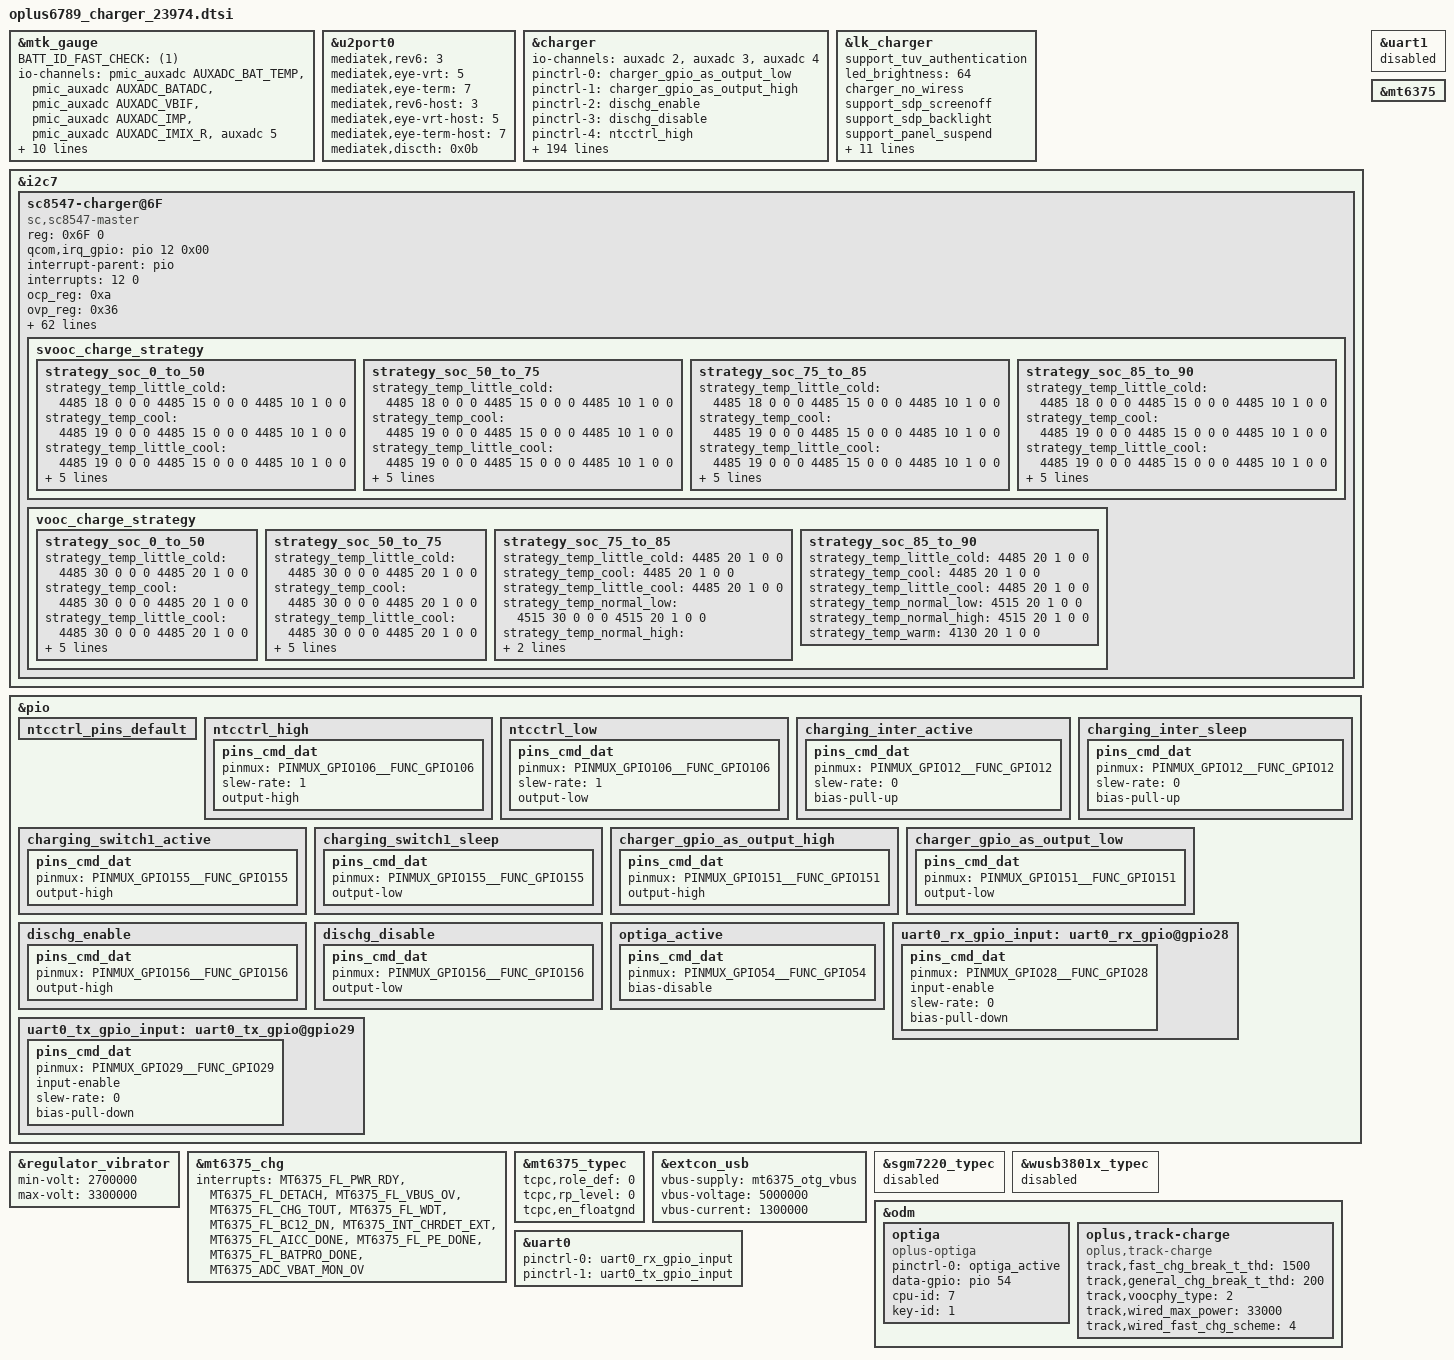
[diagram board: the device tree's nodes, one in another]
/*
 *
 * CPU:MT6789 changzheng
 * IRQB
 * CHG_INT(cp irq)                --> GPIO12(CP1)/GPIO10(CP2)
 * CC_INTB(cc login irq)          --> GPIO3
 * EINT_CHG_M(main irq)           --> GPIO4
 *
 * GPIO
 * MAIN/CCLOGIN_SCL               --> GPIO48(SCL5)
 * MAIN/CCLOGIN_SDA               --> GPIO49(SDA5)
 * SW_CTRL(uart/vooc switch)      --> GPIO155(USB_SWITCH_2)
 * DISCHARGE_EN(防烧口)           -->
 * CHARGER_PUMP1_SCL               --> GPIO144(CP1_SCL7)
 * CHARGER_PUMP1_SDA               --> GPIO145(CP1_SDA7)
 * USB_ON(usb/uart&vooc switch)    --> GPIO151(USB_SWITCH_1)
 *
 * AUXADC:
 * 0				-->
 * 1				-->
 * 2				--> USB_TEM1_ADC
 * 3				--> USB_TEM2_ADC
 * 4				--> BAT_ID_ADC_OUT
 * 5				--> SUB_BAT_TEM
 * 6				-->
 * 7				-->
 * 8				-->
 */

#include <dt-bindings/iio/mt635x-auxadc.h>
#include <dt-bindings/mfd/mt6375.h>

&mtk_gauge {
	status = "okay";
	BATT_ID_FAST_CHECK = <(1)>;
	io-channels = <&pmic_auxadc AUXADC_BAT_TEMP>,
		<&pmic_auxadc AUXADC_BATADC>,
		<&pmic_auxadc AUXADC_VBIF>,
		<&pmic_auxadc AUXADC_IMP>,
		<&pmic_auxadc AUXADC_IMIX_R>,
		<&auxadc 5>;
	io-channel-names = "pmic_battery_temp",
		"pmic_battery_voltage",
		"pmic_bif_voltage",
		"pmic_ptim_voltage",
		"pmic_ptim_r",
		"auxadc4-batt_id_v";
	charger = <&mt6375_chg>;
	FUELGAGUE_APPLY = <(1)>;
	ntc_switch_gpio = <&pio 106 0x00>;
	NTC_SWITCH_NOT_USE = <(1)>;
	//IS_SUBBOARD_TEMP_SUPPORT = <(1)>;
	Enable_Is_Force_Full = <(1)>;
	DIM2_TABLE_DISTINGUISH = <(1)>;
	EMBEDDED_SEL = <(1)>;
	CAR_TUNE_VALUE = <(99)>;
	FG_METER_RESISTANCE = <70>;
	COM_FG_METER_RESISTANCE = <70>;
	#include "mediatek/bat_setting/mt6789_23974_battery_prop_dim2_ext.dtsi"
	#include "mediatek/bat_setting/mt6789_23974_battery_table_ext.dtsi"
};

&u2port0 {
	mediatek,rev6 = <3>;
	mediatek,eye-vrt = <5>;
	mediatek,eye-term = <7>;
	mediatek,rev6-host = <3>;
	mediatek,eye-vrt-host = <5>;
	mediatek,eye-term-host = <7>;
	mediatek,discth = <0x0b>;
};

&charger {

	io-channels = <&auxadc 2>,<&auxadc 3>,<&auxadc 4>;
	io-channel-names = "usb_temp_v_l","usb_temp_v_r",
		"auxadc3-chargeric_temp";

	pinctrl-names = "charger_gpio_as_output_low","charger_gpio_as_output_high",
		"dischg_enable","dischg_disable","ntcctrl_high","ntcctrl_low";
	pinctrl-0 = <&charger_gpio_as_output_low>;
	pinctrl-1 = <&charger_gpio_as_output_high>;
	pinctrl-2 = <&dischg_enable>;
	pinctrl-3 = <&dischg_disable>;
	pinctrl-4 = <&ntcctrl_high>;
	pinctrl-5 = <&ntcctrl_low>;

	gauge = <&mtk_gauge>;
	charger = <&mt6375_chg>;

	//for oplus chg framework:
	qcom,pd_input_current_charger_ma = <2000>;
	qcom,qc_input_current_charger_ma = <2000>;
	qcom,input_current_charger_ma = <2200>;
	qcom,input_current_usb_ma = <500>;
	qcom,input_current_cdp_ma = <1500>;
	qcom,input_current_camera_ma = <1200>;
	qcom,input_current_calling_ma = <1500>;

	qcom,led_warm_bat_decidegc = <350>;
	qcom,led_high_bat_decidegc = <370>;
	qcom,input_current_led_ma = <1500>;
	qcom,input_current_led_ma_high = <1500>;
	qcom,input_current_led_ma_warm = <2000>;
	qcom,input_current_led_ma_normal = <2000>;
	qcom,input_current_led_ma_forcmcc = <500>;
	qcom,input_current_led_ma_limit_high = <1500>;

	qcom,vooc_temp_bat_normal_decidegc = <350>;
	qcom,vooc_temp_bat_warm_decidegc = <370>;
	qcom,vooc_temp_bat_hot_decidegc = <440>;
	qcom,input_current_vooc_led_ma_high = <1200>;
	qcom,input_current_vooc_led_ma_warm = <1800>;
	qcom,input_current_vooc_led_ma_normal = <3600>;
	qcom,input_current_vooc_ma_normal = <3600>;
	qcom,input_current_vooc_ma_warm = <3200>;
	qcom,input_current_vooc_ma_high = <2200>;

	qcom,overtemp_bat_decidegc = <400>;
	qcom,iterm_disabled = <0>;
	//sw_full_count = <25>;
	qcom,iterm_ma = <404>;
	qcom,recharge-mv = <100>;

	qcom,batt_capacity_mah = <7880>; /*typical capacity*/
	//qcom,batt_capacity_mah = <4880>; /*rated capacity*/
	qcom,usb_high_than_bat_decidegc = <168>;

	qcom,removed_bat_decidegc = <390>;  /* < -39C */

	qcom,cold_bat_decidegc = <100>;  /* -10C ~ 0C */
	qcom,temp_cold_vfloat_mv = <4435>;
	qcom,temp_freeze_fastchg_current_ma_high = <1500>;
	qcom,temp_freeze_fastchg_current_ma_low = <1500>;
	qcom,temp_freeze_fastchg_current_ma = <1500>;
	qcom,temp_cold_fastchg_current_ma_high = <1500>;
	qcom,temp_cold_fastchg_current_ma_low = <1500>;
	qcom,temp_cold_fastchg_current_ma = <1500>;

	qcom,little_cold_bat_decidegc = <0>;    /* 0C ~ 5C */
	qcom,temp_little_cold_vfloat_mv = <4435>;
	qcom,temp_little_cold_fastchg_current_ma_high = <2000>;
	qcom,temp_little_cold_fastchg_current_ma_low = <2000>;
	qcom,temp_little_cold_fastchg_current_ma = <2000>;
	qcom,qc_temp_little_cold_fastchg_current_ma_high = <3000>;
	qcom,qc_temp_little_cold_fastchg_current_ma_low = <2700>;
	qcom,pd_temp_little_cold_fastchg_current_ma_high = <3000>;
	qcom,pd_temp_little_cold_fastchg_current_ma_low = <2700>;

	qcom,cool_bat_decidegc = <50>;  /* 5C ~ 12C */
	qcom,temp_cool_vfloat_mv = <4435>;
	qcom,temp_cool_fastchg_current_ma_high = <2000>;
	qcom,temp_cool_fastchg_current_ma_low = <2000>;
	qcom,qc_temp_cool_fastchg_current_ma_high = <3000>;
	qcom,qc_temp_cool_fastchg_current_ma_low = <3000>;
	qcom,pd_temp_cool_fastchg_current_ma_high = <3000>;
	qcom,pd_temp_cool_fastchg_current_ma_low = <3000>;

	qcom,little_cool_bat_decidegc = <120>;  /* 12C ~ 16C */
	qcom,temp_little_cool_vfloat_mv = <4435>;
	qcom,temp_little_cool_fastchg_current_ma = <2000>;
	qcom,pd_temp_little_cool_fastchg_current_ma = <3000>;
	qcom,qc_temp_little_cool_fastchg_current_ma = <3000>;

	qcom,normal_bat_decidegc = <160>;       /* 16C ~ 45C */
	qcom,temp_normal_vfloat_mv = <4435>;
	qcom,temp_normal_fastchg_current_ma = <2000>;
	qcom,pd_temp_normal_fastchg_current_ma = <3000>;
	qcom,qc_temp_normal_fastchg_current_ma = <3000>;

	qcom,warm_bat_decidegc = <450>;         /* 45C ~ 53C */ /*8pin Bat Vooc project need add 3 degree C*/
	qcom,temp_warm_vfloat_mv = <4130>;
	qcom,temp_warm_fastchg_current_ma = <1152>;
	qcom,pd_temp_warm_fastchg_current_ma = <1152>;
	qcom,qc_temp_warm_fastchg_current_ma = <1152>;
	qcom,temp_warm_fastchg_current_ma_led_on = <500>;

	qcom,hot_bat_decidegc = <530>;  /* > 53C */

	qcom,non_standard_vfloat_mv = <3980>;
	qcom,non_standard_fastchg_current_ma = <512>;

	qcom,short_c_bat_cv_mv = <4330>;
	qcom,short_c_bat_vfloat_mv = <3800>;
	qcom,short_c_bat_fastchg_current_ma = <512>;
	qcom,short_c_bat_vfloat_sw_limit = <3750>;

	qcom,cold_vfloat_sw_limit = <4385>;
	qcom,little_cold_vfloat_sw_limit = <4385>;
	qcom,cool_vfloat_sw_limit = <4385>;
	qcom,little_cool_vfloat_sw_limit = <4385>;
	qcom,normal_vfloat_sw_limit = <4385>;
	qcom,warm_vfloat_sw_limit = <4080>;
	qcom,non_standard_vfloat_sw_limit = <3930>;

	qcom,max_chg_time_sec = <72000>;
	qcom,charger_hv_thr = <10000>;
	qcom,charger_recv_thr = <9800>;
	qcom,charger_lv_thr = <3400>;
	qcom,vbatt_full_thr = <4400>;
	qcom,vbatt_hv_thr = <4600>;

	qcom,vfloat_step_mv = <16>;
	qcom,non_standard_vfloat_over_sw_limit = <3990>;
	qcom,cold_vfloat_over_sw_limit = <4445>;
	qcom,little_cold_vfloat_over_sw_limit = <4445>;
	qcom,cool_vfloat_over_sw_limit = <4445>;
	qcom,little_cool_vfloat_over_sw_limit = <4445>;
	qcom,normal_vfloat_over_sw_limit = <4440>;
	qcom,warm_vfloat_over_sw_limit = <4140>;

	qcom,vbatt_power_off = <3300>;
	qcom,vbatt_soc_1 = <3410>;
	qcom,vooc_project = <5>;
	qcom,vbatt_num = <1>;
	qcom,new_ui_warning_support;
	qcom,smart_charging_screenoff;
	qcom,smart_charge_version = <1>;

	qcom,normal_vterm_hw_inc = <18>;
	qcom,non_normal_vterm_hw_inc = <18>;
	qcom,usbtemp_batttemp_gap = <12>;

	qcom,ff1_normal_fastchg_ma = <1800>;
	qcom,ff1_warm_fastchg_ma = <2200>;	/* 35C ~ 40c */
	qcom,ff1_exit_step_ma = <100>;
	qcom,ff1_warm_exit_step_ma = <100>;
	qcom,ffc2_normal_fastchg_ma = <1800>;/*12C~35c*/
	qcom,ffc2_warm_fastchg_ma = <2200>;	/* 35C ~ 40c */
	qcom,ffc2_temp_warm_decidegc = <350>;
	qcom,ffc2_temp_high_decidegc = <400>;
	qcom,ffc2_temp_low_decidegc = <160>;
	qcom,ffc2_exit_step_ma = <100>;
	qcom,ffc2_warm_exit_step_ma = <100>;

	qcom,ffc_normal_vfloat_sw_limit = <4515>;
	qcom,ffc2_normal_vfloat_sw_limit = <4515>;
	qcom,ffc_temp_normal_vfloat_mv = <4550>;
	qcom,ffc_normal_vfloat_over_sw_limit = <4550>;

	qcom,default_iterm_ma = <404>;
	qcom,default_temp_normal_fastchg_current_ma = <2200>;
	qcom,default_normal_vfloat_sw_limit = <4385>;
	qcom,default_temp_normal_vfloat_mv = <4435>;
	qcom,default_normal_vfloat_over_sw_limit = <4445>;

	qcom,default_temp_little_cool_fastchg_current_ma = <2200>;
	qcom,default_little_cool_vfloat_sw_limit = <4385>;
	qcom,default_temp_little_cool_vfloat_mv = <4435>;
	qcom,default_little_cool_vfloat_over_sw_limit = <4445>;

	//for PD9V or QC9V
	qcom,vbatt_pdqc_to_5v_thr = <4500>;
	qcom,vbatt_pdqc_to_9v_thr = <4500>;

	//for control:
	//qcom,suspend_after_full;
	qcom,check_batt_full_by_sw;
	qcom,chg_ctrl_by_lcd;
	qcom,chg_ctrl_by_camera;
	qcom,chg_ctrl_by_calling;
	qcom,sw_vfloat_over_protect_enable;
	//qcom,usbtemp_dischg_by_platpmic;
	//qcom,usbtemp_dischg_by_pmic;
	qcom,ffc_support;
	qcom,chargerid_vol_disable;
	qcom,support_ntc_01c_precision;
	qcom,voocphy_support = <2>;
	//qcom,external_authenticate;
	qcom,chargerid_support;
	qcom,vooc_show_ui_soc_decimal;
	qcom,ui_soc_decimal_speedmin = <20>;//2A
	qcom,ccdetect_by_wd0;
	//qcom,hvdcp_disabled;
	//qcom,ntc_switch_used;
	//GPIO config:
	qcom,chargerid_switch-gpio = <&pio 151 0x00>;
	qcom,dischg-gpio = <&pio 156 0x00>;
	//qcom,ntcctrl-gpio = <&pio 106 0x00>;
	//qcom,ccdetect-gpio = <&pio 3 0x00>;

	qcom,vooc-max-input-volt-support = <11000>;     //10V
	qcom,vooc-max-input-current-support = <3000>;   //3A
	qcom,support_3p6_standard;
	qcom,support_mt6375_charger;

	qcom,support_usbtemp_protect_v2;
	qcom,usbtemp_batt_temp_low = <50>;
	qcom,usbtemp_batt_temp_high = <50>;
	qcom,usbtemp_ntc_temp_low = <57>;
	qcom,usbtemp_ntc_temp_high = <69>;
	qcom,usbtemp_temp_gap_low_with_batt_temp = <7>;
	qcom,usbtemp_temp_gap_high_with_batt_temp = <12>;
	qcom,usbtemp_temp_gap_low_without_batt_temp = <12>;
	qcom,usbtemp_temp_gap_high_without_batt_temp = <24>;
	qcom.usbtemp_rise_fast_temp_low = <3>;
	qcom.usbtemp_rise_fast_temp_high = <3>;
	qcom.usbtemp_rise_fast_temp_count_low = <30>;
	qcom.usbtemp_rise_fast_temp_count_high = <20>;

	qcom,usbtemp_cool_down_ntc_low = <54>;
	qcom,usbtemp_cool_down_ntc_high = <65>;
	qcom,usbtemp_cool_down_gap_low = <12>;
	qcom,usbtemp_cool_down_gap_high = <20>;
	qcom,usbtemp_cool_down_recover_ntc_low = <48>;
	qcom,usbtemp_cool_down_recover_ntc_high = <60>;
	qcom,usbtemp_cool_down_recover_gap_low = <6>;
	qcom,usbtemp_cool_down_recover_gap_high = <15>;
};

&lk_charger {
	support_tuv_authentication;
	led_brightness = <64>;
	charger_no_wiress;
	support_sdp_screenoff;
	support_sdp_backlight;
	support_panel_suspend;
	is_support_mt6375;
	//charger_by_bq2589x;
	//sub_board_temp_support;
	support_battery_type = <1>;
	max_charger_voltage = <15000000>;
	boot_battery_voltage = <3400000>;
	usb_charger_current = <500000>;
	ac_charger_current = <2000000>;
	ac_charger_input_current = <2200000>;
	non_std_ac_charger_current = <2000000>;
	charging_host_charger_current = <1600000>;
	ta_ac_charger_current = <1500000>;
	pd_charger_current = <500000>;
};

&i2c7 {
	status = "okay";
	sc8547-charger@6F{
		status = "okay";
		compatible = "sc,sc8547-master";
		reg = <0x6F 0>;

		qcom,irq_gpio = <&pio 12 0x00>;
		interrupt-parent = <&pio>;
		interrupts = <12 0>;
		ocp_reg = <0xa>;
		ovp_reg = <0x36>;

		pinctrl-names = "switch1_act_switch2_act", "switch1_sleep_switch2_sleep",
					"charging_inter_active", "charging_inter_sleep";
		pinctrl-0 = <&charging_switch1_active>;
		pinctrl-1 = <&charging_switch1_sleep>;
		pinctrl-2 = <&charging_inter_active>;
		pinctrl-3 = <&charging_inter_sleep>;

		qcom,charging_switch1-gpio = <&pio 155 0x00>;
		qcom,copycat_vooc_support;
		oplus,copycat_identify_algorithm = <2>;

		qcom,voocphy_current_default = <30>;

		qcom,svooc_cool_down_current_limit = <60 20 20 20 30 40 50 60 60 60 60 60>;
		qcom,vooc_cool_down_current_limit = <60 20 20 20 30 40 50 60>;

		qcom,vooc_little_cold_full_voltage = <4485>;
		qcom,vooc_cool_full_voltage = <4485>;
		qcom,vooc_little_cool_full_voltage = <4485>;
		qcom,vooc_warm_full_voltage = <4130>;
		qcom,vooc_1time_full_voltage = <4530>;
		qcom,vooc_ntime_full_voltage = <4520>;
		qcom,low_curr_full_t1 = <120>;
		qcom,low_curr_full_t2 = <350>;
		qcom,low_curr_full_t3 = <430>;
		qcom,range1_low_curr_full = <1100 4480
						1000 4475
						900 4470
						800 4460
						700 4450>;
		qcom,range2_low_curr_full = <1200 4480
						1100 4475
						1000 4470
						900 4460
						800 4450>;

		qcom,vooc_multistep_initial_batt_temp = <1000>;
		qcom,vooc_little_cool_temp = <160>;
		qcom,vooc_cool_temp = <120>;
		qcom,vooc_little_cold_temp = <50>;
		qcom,vooc_normal_low_temp = <250>;
		qcom,vooc_strategy_normal_current = <100>;
		qcom,vooc_normal_to_little_cool_current = <100>;
		qcom,vooc_batt_over_high_temp = <510>;
		qcom,vooc_batt_over_low_temp = <0>;

		qcom,vooc-high-temp = <500>;
		qcom,vooc-low-soc = <0>;
		qcom,vooc-high-soc = <90>;
		qcom,vooc-normal-high-temp = <430>;
		qcom,vooc-warm-allow-vol = <4130>;
		qcom,vooc-warm-allow-soc = <50>;

		qcom,vooc_strategy1_batt_high_temp0 = <395>;
		qcom,vooc_strategy1_batt_high_temp1 = <420>;
		qcom,vooc_strategy1_batt_high_temp2 = <440>;
		qcom,vooc_strategy1_batt_low_temp2 = <420>;
		qcom,vooc_strategy1_batt_low_temp1 = <395>;
		qcom,vooc_strategy1_batt_low_temp0 = <385>;

		qcom,vooc_strategy1_high_current0 = <60>;
		qcom,vooc_strategy1_high_current1 = <60>;
		qcom,vooc_strategy1_high_current2 = <60>;
		qcom,vooc_strategy1_low_current2 = <60>;
		qcom,vooc_strategy1_low_current1 = <60>;
		qcom,vooc_strategy1_low_current0 = <60>;

		qcom,voocphy_freq_mincore = <968000>;
		qcom,voocphy_freq_midcore = <1418000>;
		qcom,voocphy_freq_maxcore = <1418000>;
		qcom,voocphy_current_change_timeout = <100>;

		qcom,voocphy_ibat_over_current = <11500>;
		qcom,voocphy_cp_max_ibus = <3500>;

		svooc_batt_sys_curve = <0 0 1 1 1 1 0	// 3000mA
					1 1 1 1 0 0 0 	// 4604mV
					0 0 1 0 1 0 0	// 2000mA
					1 1 1 1 0 0 0	// 4604mV
					0 0 0 1 0 1 0	// 1000mA
					1 1 1 1 0 0 0>;	// 4604mV

		vooc_batt_sys_curve =  <0 0 1 1 1 1 0	// 3000mA
					1 1 1 1 0 0 0 	// 4604mV
					0 0 1 0 1 0 0	// 2000mA
					1 1 1 1 0 0 0	// 4604mV
					0 0 0 1 0 1 0	// 1000mA
					1 1 1 1 0 0 0>;	// 4604mV

		svooc_charge_strategy {
			strategy_soc_0_to_50 {
				strategy_temp_little_cold = <4485 18 0 0 0
					4485 15 0 0 0
					4485 10 1 0 0>; /* 0-5C */
				strategy_temp_cool = <4485 19 0 0 0
					4485 15 0 0 0
					4485 10 1 0 0>; /* 5-12C */
				strategy_temp_little_cool = <4485 19 0 0 0
					4485 15 0 0 0
					4485 10 1 0 0>; /* 12-16C */
				strategy_temp_normal_low = <4400 30 0 1200 0  //min*60*1000/500
					4400 25 0 1200 0  //min*60*1000/500
					4515 23 0 0 0
					4515 20 0 0 0
					4515 15 0 0 0
					4520 10 1 0 0>; /* 16-25C */
				strategy_temp_normal_high = <4400 30 0 1200 0  //min*60*1000/500
					4400 25 0 1200 0  //min*60*1000/500
					4515 23 0 0 0
					4515 20 0 0 0
					4515 15 0 0 0
					4520 10 1 0 0>;/*25C-43C*/
				strategy_temp_warm = <4130 20 1 0 0>; /* 43-53 */
			};

			strategy_soc_50_to_75 {
				strategy_temp_little_cold = <4485 18 0 0 0
					4485 15 0 0 0
					4485 10 1 0 0>; /* 0-5C */
				strategy_temp_cool = <4485 19 0 0 0
					4485 15 0 0 0
					4485 10 1 0 0>; /* 5-12C */
				strategy_temp_little_cool = <4485 19 0 0 0
					4485 15 0 0 0
					4485 10 1 0 0>; /* 12-16C */
				strategy_temp_normal_low = <4400 30 0 1200 0  //min*60*1000/500
					4400 25 0 1200 0  //min*60*1000/500
					4515 23 0 0 0
					4515 20 0 0 0
					4515 15 0 0 0
					4520 10 1 0 0>; /* 16-25C */
				strategy_temp_normal_high = <4400 30 0 1200 0  //min*60*1000/500
					4400 25 0 1200 0  //min*60*1000/500
					4515 23 0 0 0
					4515 20 0 0 0
					4515 15 0 0 0
					4520 10 1 0 0>;/*25C-43C*/
				strategy_temp_warm = <4130 20 1 0 0>; /* 43-53 */
			};

			strategy_soc_75_to_85 {
				strategy_temp_little_cold = <4485 18 0 0 0
					4485 15 0 0 0
					4485 10 1 0 0>; /* 0-5C */
				strategy_temp_cool = <4485 19 0 0 0
					4485 15 0 0 0
					4485 10 1 0 0>; /* 5-12C */
				strategy_temp_little_cool = <4485 19 0 0 0
					4485 15 0 0 0
					4485 10 1 0 0>; /* 12-16C */
				strategy_temp_normal_low = <4515 23 0 1200 0  //min*60*1000/500
					4515 20 0 0 0
					4515 15 0 0 0
					4520 10 1 0 0>; /* 16-25C */
				strategy_temp_normal_high = <4515 23 0 1200 0  //min*60*1000/500
					4515 20 0 0 0
					4515 15 0 0 0
					4520 10 1 0 0>;/*25C-43C*/
				strategy_temp_warm = <4130 10 1 0 0>; /* 43-53 */
			};

			strategy_soc_85_to_90 {
				strategy_temp_little_cold = <4485 18 0 0 0
					4485 15 0 0 0
					4485 10 1 0 0>; /* 0-5C */
				strategy_temp_cool = <4485 19 0 0 0
					4485 15 0 0 0
					4485 10 1 0 0>; /* 5-12C */
				strategy_temp_little_cool = <4485 19 0 0 0
					4485 15 0 0 0
					4485 10 1 0 0>; /* 12-16C */
				strategy_temp_normal_low = <4515 23 0 1200 0  //min*60*1000/500
					4515 20 0 0 0
					4515 15 0 0 0
					4520 10 1 0 0>; /* 16-25C */
				strategy_temp_normal_high = <4515 23 0 1200 0  //min*60*1000/500
					4515 20 0 0 0
					4515 15 0 0 0
					4520 10 1 0 0>;/*25C-43C*/
				strategy_temp_warm = <4130 10 1 0 0>; /* 43-53 */
			};
		};

		vooc_charge_strategy {
			strategy_soc_0_to_50 {
				strategy_temp_little_cold = <4485 30 0 0 0
					4485 20 1 0 0>; /* 0-5C */
				strategy_temp_cool = <4485 30 0 0 0
					4485 20 1 0 0>; /* 5-12C */
				strategy_temp_little_cool = <4485 30 0 0 0
					4485 20 1 0 0>; /* 12-16C */
				strategy_temp_normal_low = <4515 30 0 0 0
					4515 20 1 0 0>; /* 16-25C */
				strategy_temp_normal_high = <4515 30 0 0 0
					4515 20 1 0 0>;/*25C-43C*/
				strategy_temp_warm = <4130 30 1 0 0>; /* 43-53 */
			};

			strategy_soc_50_to_75 {
				strategy_temp_little_cold = <4485 30 0 0 0
					4485 20 1 0 0>; /* 0-5C */
				strategy_temp_cool = <4485 30 0 0 0
					4485 20 1 0 0>; /* 5-12C */
				strategy_temp_little_cool = <4485 30 0 0 0
					4485 20 1 0 0>; /* 12-16C */
				strategy_temp_normal_low = <4515 30 0 0 0
					4515 20 1 0 0>; /* 16-25C */
				strategy_temp_normal_high = <4515 30 0 0 0
					4515 20 1 0 0>;/*25C-43C*/
				strategy_temp_warm = <4130 20 1 0 0>; /* 43-53 */
			};

			strategy_soc_75_to_85 {
				strategy_temp_little_cold = <4485 20 1 0 0>; /* 0-5C */
				strategy_temp_cool = <4485 20 1 0 0>; /* 5-12C */
				strategy_temp_little_cool = <4485 20 1 0 0>; /* 12-16C */
				strategy_temp_normal_low = <4515 30 0 0 0
					4515 20 1 0 0>; /* 16-25C */
				strategy_temp_normal_high = <4515 30 0 0 0
					4515 20 1 0 0>;/*25C-43C*/
				strategy_temp_warm = <4130 20 1 0 0>; /* 43-53 */
			};

			strategy_soc_85_to_90 {
				strategy_temp_little_cold = <4485 20 1 0 0>; /* 0-5C */
				strategy_temp_cool = <4485 20 1 0 0>; /* 5-12C */
				strategy_temp_little_cool = <4485 20 1 0 0>; /* 12-16C */
				strategy_temp_normal_low = <4515 20 1 0 0>; /* 16-25C */
				strategy_temp_normal_high = <4515 20 1 0 0>;/*25C-43C*/
				strategy_temp_warm = <4130 20 1 0 0>; /* 43-53 */
			};
		};
	};
};

&pio {
	ntcctrl_pins_default: ntcctrl_pins_default {
	};

	ntcctrl_high: ntcctrl_high {
		pins_cmd_dat {
			pinmux = <PINMUX_GPIO106__FUNC_GPIO106>;
			slew-rate = <1>;//0:input direction 1:output direction
			output-high;
		};
	};

	ntcctrl_low: ntcctrl_low {
		pins_cmd_dat {
			pinmux = <PINMUX_GPIO106__FUNC_GPIO106>;
			slew-rate = <1>;
			output-low;
		};
	};
};

&uart1 {
	status = "disabled";
};

&pio {
	charging_inter_active: charging_inter_active {
		pins_cmd_dat {
			pinmux = <PINMUX_GPIO12__FUNC_GPIO12>;
			slew-rate = <0>;
			bias-pull-up;
		};
	};

	charging_inter_sleep: charging_inter_sleep {
		pins_cmd_dat {
			pinmux = <PINMUX_GPIO12__FUNC_GPIO12>;
			slew-rate = <0>;
			bias-pull-up;
		};
	};

	charging_switch1_active: charging_switch1_active {
		pins_cmd_dat {
			pinmux = <PINMUX_GPIO155__FUNC_GPIO155>;
			output-high;
		};
	};

	charging_switch1_sleep: charging_switch1_sleep {
		pins_cmd_dat {
			pinmux = <PINMUX_GPIO155__FUNC_GPIO155>;
			output-low;
		};
	};

	charger_gpio_as_output_high: charger_gpio_as_output_high {
		pins_cmd_dat {
			pinmux = <PINMUX_GPIO151__FUNC_GPIO151>;
			output-high;
		};
	};
	charger_gpio_as_output_low: charger_gpio_as_output_low {
		pins_cmd_dat {
			pinmux = <PINMUX_GPIO151__FUNC_GPIO151>;
			output-low;
		};
	};
	dischg_enable: dischg_enable {
		pins_cmd_dat {
			pinmux = <PINMUX_GPIO156__FUNC_GPIO156>;
			output-high;
		};
	};
	dischg_disable: dischg_disable {
		pins_cmd_dat {
			pinmux = <PINMUX_GPIO156__FUNC_GPIO156>;
			output-low;
		};
	};
};

&regulator_vibrator{
	min-volt = <2700000>;
	max-volt = <3300000>;
};

&mt6375 {
	status = "okay";
};

&mt6375_chg {
	interrupts = <MT6375_FL_PWR_RDY>, <MT6375_FL_DETACH>,
		     <MT6375_FL_VBUS_OV>, <MT6375_FL_CHG_TOUT>,
		     <MT6375_FL_WDT>, <MT6375_FL_BC12_DN>,
		     <MT6375_INT_CHRDET_EXT>,
		     <MT6375_FL_AICC_DONE>, <MT6375_FL_PE_DONE>,
		     <MT6375_FL_BATPRO_DONE>,
		     <MT6375_ADC_VBAT_MON_OV>;
	interrupt-names = "fl_pwr_rdy", "fl_detach",
		     "fl_vbus_ov", "fl_chg_tout",
		     "fl_wdt", "fl_bc12_dn",
		     "int_chrdet_ext",
		     "fl_aicc_done", "fl_pe_done",
		     "fl_batpro_done", "adc_vbat_mon_ov";
};

&charger {
	charger = <&mt6375_chg>;
	status = "okay";
};

&mt6375_typec {
	tcpc,role_def = <0>;
	tcpc,rp_level = <0>;
	tcpc,en_floatgnd;
};

&extcon_usb {
	vbus-supply = <&mt6375_otg_vbus>;
	vbus-voltage = <5000000>;
	vbus-current = <1300000>;
};

&sgm7220_typec {
	status = "disabled";
};

&wusb3801x_typec {
	status = "disabled";
};

&odm {
	optiga {
		compatible = "oplus-optiga";
		status = "ok";
		pinctrl-names = "optiga_active";
		pinctrl-0 = <&optiga_active>;
		data-gpio = <&pio 54 0x00>;
		cpu-id = <7>;
		key-id = <1>;
	};

	oplus,track-charge {
		compatible = "oplus,track-charge";
		track,fast_chg_break_t_thd = <1500>;
		track,general_chg_break_t_thd = <200>;
		track,voocphy_type = <2>;
		track,wired_max_power = <33000>;
		track,wired_fast_chg_scheme = <4>;
	};
};


&pio {
	optiga_active: optiga_active {
		pins_cmd_dat {
			pinmux = <PINMUX_GPIO54__FUNC_GPIO54>;
			//slew-rate = <1>;
			bias-disable;
		};
	};
};

&uart0 {
	pinctrl-names = "uart0_rx_gpio",
		"uart0_tx_gpio";
	pinctrl-0 = <&uart0_rx_gpio_input>;
	pinctrl-1 = <&uart0_tx_gpio_input>;
	status = "okay";
};

&pio {
	uart0_rx_gpio_input:uart0_rx_gpio@gpio28 {
		pins_cmd_dat {
			pinmux = <PINMUX_GPIO28__FUNC_GPIO28>;
			input-enable;
			slew-rate = <0>;
			bias-pull-down;
		};
	};

	uart0_tx_gpio_input:uart0_tx_gpio@gpio29 {
		pins_cmd_dat {
			pinmux = <PINMUX_GPIO29__FUNC_GPIO29>;
			input-enable;
			slew-rate = <0>;
			bias-pull-down;
		};
	};
};
